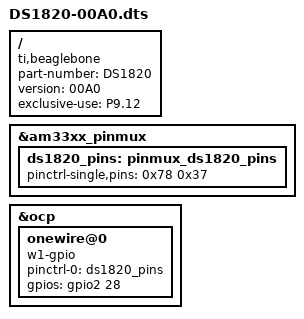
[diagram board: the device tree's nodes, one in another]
/dts-v1/;
/plugin/;
 
/ {
    compatible = "ti,beaglebone", "ti,beaglebone-black";
    part-number = "DS1820";
    version = "00A0";
 
    exclusive-use = "P9.12";
 
    fragment@0 {
        target = <&am33xx_pinmux>;
        __overlay__ {
             ds1820_pins: pinmux_ds1820_pins {
                 pinctrl-single,pins =  <0x78 0x37>;
             };
        };
    };
 
    fragment@1 {
        target = <&ocp>;
        __overlay__ {
            onewire@0 {
                status          = "okay";
                compatible      = "w1-gpio";
                pinctrl-names   = "default";
                pinctrl-0       = <&ds1820_pins>;
                gpios           = <&gpio2 28 0>;
            };
        };
    };
};
